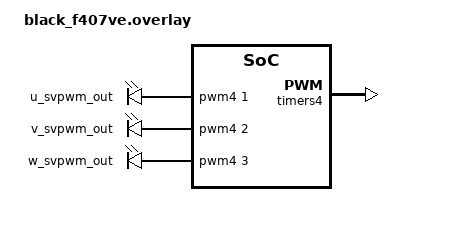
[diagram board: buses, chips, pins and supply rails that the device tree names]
/ {
	svpwm {
		compatible = "pwm-leds";//compatible is necessay.
		
		u_svpwm_out:u_svpwm_out{
			pwms = <&pwm4 1 33333 PWM_POLARITY_NORMAL>;
		};
		v_svpwm_out:v_svpwm_out{
			pwms = <&pwm4 2 33333 PWM_POLARITY_NORMAL>;
		};
		w_svpwm_out:w_svpwm_out{
			pwms = <&pwm4 3 33333 PWM_POLARITY_NORMAL>;
		};
	};
	
};

&tim4_ch1_pd12 {
	slew-rate = "very-high-speed";
	bias-disable;
	drive-push-pull;
};
&tim4_ch2_pd13 {
	slew-rate = "very-high-speed";
	bias-disable;
	drive-push-pull;
};
&tim4_ch3_pd14 {
	slew-rate = "very-high-speed";
	bias-disable;
	drive-push-pull;
};

&timers4 {
	status = "okay";
	pwm4:pwm {
		status = "okay";
		//Pin configuration/s for the first state
		pinctrl-0 = <&tim4_ch1_pd12 &tim4_ch2_pd13 &tim4_ch3_pd14>;
		pinctrl-names = "default";
	};
};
